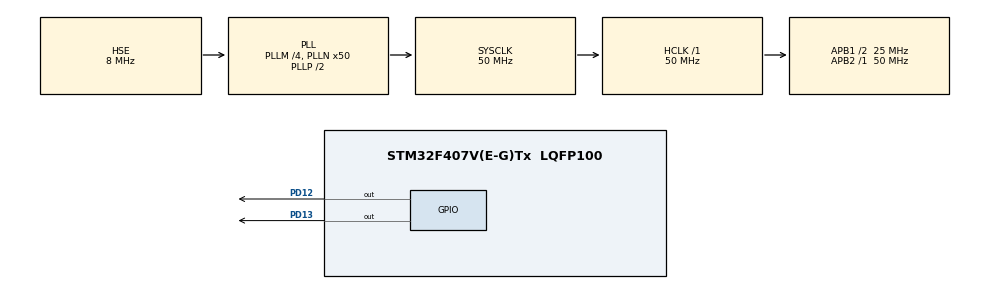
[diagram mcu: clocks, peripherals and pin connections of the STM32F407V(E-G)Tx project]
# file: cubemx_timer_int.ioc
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Mcu.Family=STM32F4
Mcu.Name=STM32F407V(E-G)Tx
Mcu.Package=LQFP100
NVIC.PriorityGroup=NVIC_PRIORITYGROUP_4
NVIC.TIM6_DAC_IRQn=true\:0\:0\:false\:true\:true\:2\:true\:true\:true
NVIC.TIM7_IRQn=true\:0\:0\:false\:true\:true\:1\:true\:true\:true
PD12.Signal=GPIO_Output
PD13.Signal=GPIO_Output
PH0-OSC_IN.Mode=HSE-External-Oscillator
PH0-OSC_IN.Signal=RCC_OSC_IN
PH1-OSC_OUT.Mode=HSE-External-Oscillator
PH1-OSC_OUT.Signal=RCC_OSC_OUT
ProjectManager.HeapSize=0x200
ProjectManager.StackSize=0x400
ProjectManager.TargetToolchain=STM32CubeIDE
RCC.48MHZClocksFreq_Value=25000000
RCC.AHBFreq_Value=50000000
RCC.APB1CLKDivider=RCC_HCLK_DIV2
RCC.APB1Freq_Value=25000000
RCC.APB1TimFreq_Value=50000000
RCC.APB2Freq_Value=50000000
RCC.APB2TimFreq_Value=50000000
RCC.CortexFreq_Value=50000000
RCC.HCLKFreq_Value=50000000
RCC.HSE_VALUE=8000000
RCC.HSI_VALUE=16000000
RCC.LSE_VALUE=32768
RCC.PLLM=4
RCC.PLLN=50
RCC.PLLSourceVirtual=RCC_PLLSOURCE_HSE
RCC.SYSCLKFreq_VALUE=50000000
RCC.SYSCLKSource=RCC_SYSCLKSOURCE_PLLCLK
RCC.VCOOutputFreq_Value=100000000
TIM6.AutoReloadPreload=TIM_AUTORELOAD_PRELOAD_ENABLE
TIM6.Period=500
TIM6.Prescaler=50000
TIM7.AutoReloadPreload=TIM_AUTORELOAD_PRELOAD_ENABLE
TIM7.Period=8399
TIM7.Prescaler=9999
TIM7.TIM_MasterOutputTrigger=TIM_TRGO_UPDATE
VP_TIM6_VS_ClockSourceINT.Mode=Enable_Timer
VP_TIM7_VS_ClockSourceINT.Mode=Enable_Timer
board=custom

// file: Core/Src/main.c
/* USER CODE BEGIN Header */
/**
  ******************************************************************************
  * @file           : main.c
  * @brief          : Main program body
  ******************************************************************************
  * @attention
  *
  * Copyright (c) 2024 STMicroelectronics.
  * All rights reserved.
  *
  * This software is licensed under terms that can be found in the LICENSE file
  * in the root directory of this software component.
  * If no LICENSE file comes with this software, it is provided AS-IS.
  *
  ******************************************************************************
  */
/* USER CODE END Header */
#include "main.h"

TIM_HandleTypeDef htim6;
TIM_HandleTypeDef htim7;

/* USER CODE BEGIN PV */
uint8_t f_led_12 = 0;
uint8_t f_led_13 = 0;
/* USER CODE END PV */

void SystemClock_Config(void);
static void MX_GPIO_Init(void);
static void MX_TIM7_Init(void);
static void MX_TIM6_Init(void);
static void MX_NVIC_Init(void);

int main(void)
{

  /* MCU Configuration--------------------------------------------------------*/

  /* Reset of all peripherals, Initializes the Flash interface and the Systick. */
  HAL_Init();

  /* Configure the system clock */
  SystemClock_Config();

  /* Initialize all configured peripherals */
  MX_GPIO_Init();
  MX_TIM7_Init();
  MX_TIM6_Init();

  /* Initialize interrupts */
  MX_NVIC_Init();
  /* USER CODE BEGIN 2 */
  HAL_TIM_Base_Start_IT(&htim7);
  HAL_TIM_Base_Start_IT(&htim6);
  /* USER CODE END 2 */

  /* Infinite loop */
  /* USER CODE BEGIN WHILE */
  while (1)
  {if(f_led_13 == 1){
		HAL_GPIO_TogglePin(GPIOD, GPIO_PIN_13);
		f_led_13 = 0;
	}else if (f_led_12 == 1){
		HAL_GPIO_TogglePin(GPIOD, GPIO_PIN_12);
		f_led_12 = 0;
	}
    /* USER CODE END WHILE */

  }
}

void SystemClock_Config(void)
{
  RCC_OscInitTypeDef RCC_OscInitStruct = {0};
  RCC_ClkInitTypeDef RCC_ClkInitStruct = {0};

  /** Configure the main internal regulator output voltage
  */
  __HAL_RCC_PWR_CLK_ENABLE();
  __HAL_PWR_VOLTAGESCALING_CONFIG(PWR_REGULATOR_VOLTAGE_SCALE1);

  /** Initializes the RCC Oscillators according to the specified parameters
  * in the RCC_OscInitTypeDef structure.
  */
  RCC_OscInitStruct.OscillatorType = RCC_OSCILLATORTYPE_HSE;
  RCC_OscInitStruct.HSEState = RCC_HSE_ON;
  RCC_OscInitStruct.PLL.PLLState = RCC_PLL_ON;
  RCC_OscInitStruct.PLL.PLLSource = RCC_PLLSOURCE_HSE;
  RCC_OscInitStruct.PLL.PLLM = 4;
  RCC_OscInitStruct.PLL.PLLN = 50;
  RCC_OscInitStruct.PLL.PLLP = RCC_PLLP_DIV2;
  RCC_OscInitStruct.PLL.PLLQ = 4;
  if (HAL_RCC_OscConfig(&RCC_OscInitStruct) != HAL_OK)
  {
    Error_Handler();
  }

  /** Initializes the CPU, AHB and APB buses clocks
  */
  RCC_ClkInitStruct.ClockType = RCC_CLOCKTYPE_HCLK|RCC_CLOCKTYPE_SYSCLK
                              |RCC_CLOCKTYPE_PCLK1|RCC_CLOCKTYPE_PCLK2;
  RCC_ClkInitStruct.SYSCLKSource = RCC_SYSCLKSOURCE_PLLCLK;
  RCC_ClkInitStruct.AHBCLKDivider = RCC_SYSCLK_DIV1;
  RCC_ClkInitStruct.APB1CLKDivider = RCC_HCLK_DIV2;
  RCC_ClkInitStruct.APB2CLKDivider = RCC_HCLK_DIV1;

  if (HAL_RCC_ClockConfig(&RCC_ClkInitStruct, FLASH_LATENCY_1) != HAL_OK)
  {
    Error_Handler();
  }
}

/**
  * @brief NVIC Configuration.
  * @retval None
  */
static void MX_NVIC_Init(void)
{
  /* TIM7_IRQn interrupt configuration */
  HAL_NVIC_SetPriority(TIM7_IRQn, 0, 0);
  HAL_NVIC_EnableIRQ(TIM7_IRQn);
  /* TIM6_DAC_IRQn interrupt configuration */
  HAL_NVIC_SetPriority(TIM6_DAC_IRQn, 0, 0);
  HAL_NVIC_EnableIRQ(TIM6_DAC_IRQn);
}

static void MX_TIM6_Init(void)
{

  TIM_MasterConfigTypeDef sMasterConfig = {0};

  htim6.Instance = TIM6;
  htim6.Init.Prescaler = 50000;
  htim6.Init.CounterMode = TIM_COUNTERMODE_UP;
  htim6.Init.Period = 500;
  htim6.Init.AutoReloadPreload = TIM_AUTORELOAD_PRELOAD_ENABLE;
  if (HAL_TIM_Base_Init(&htim6) != HAL_OK)
  {
    Error_Handler();
  }
  sMasterConfig.MasterOutputTrigger = TIM_TRGO_RESET;
  sMasterConfig.MasterSlaveMode = TIM_MASTERSLAVEMODE_DISABLE;
  if (HAL_TIMEx_MasterConfigSynchronization(&htim6, &sMasterConfig) != HAL_OK)
  {
    Error_Handler();
  }

}

static void MX_TIM7_Init(void)
{

  TIM_MasterConfigTypeDef sMasterConfig = {0};

  htim7.Instance = TIM7;
  htim7.Init.Prescaler = 9999;
  htim7.Init.CounterMode = TIM_COUNTERMODE_UP;
  htim7.Init.Period = 8399;
  htim7.Init.AutoReloadPreload = TIM_AUTORELOAD_PRELOAD_ENABLE;
  if (HAL_TIM_Base_Init(&htim7) != HAL_OK)
  {
    Error_Handler();
  }
  sMasterConfig.MasterOutputTrigger = TIM_TRGO_UPDATE;
  sMasterConfig.MasterSlaveMode = TIM_MASTERSLAVEMODE_DISABLE;
  if (HAL_TIMEx_MasterConfigSynchronization(&htim7, &sMasterConfig) != HAL_OK)
  {
    Error_Handler();
  }

}

static void MX_GPIO_Init(void)
{
  GPIO_InitTypeDef GPIO_InitStruct = {0};

  /* GPIO Ports Clock Enable */
  __HAL_RCC_GPIOH_CLK_ENABLE();
  __HAL_RCC_GPIOD_CLK_ENABLE();

  /*Configure GPIO pin Output Level */
  HAL_GPIO_WritePin(GPIOD, GPIO_PIN_12|GPIO_PIN_13, GPIO_PIN_RESET);

  /*Configure GPIO pins : PD12 PD13 */
  GPIO_InitStruct.Pin = GPIO_PIN_12|GPIO_PIN_13;
  GPIO_InitStruct.Mode = GPIO_MODE_OUTPUT_PP;
  GPIO_InitStruct.Pull = GPIO_NOPULL;
  GPIO_InitStruct.Speed = GPIO_SPEED_FREQ_LOW;
  HAL_GPIO_Init(GPIOD, &GPIO_InitStruct);

}

/* USER CODE BEGIN 4 */
void HAL_TIM_PeriodElapsedCallback(TIM_HandleTypeDef *htim)
{
  //if (htim == &htim7) {
    //HAL_GPIO_TogglePin(GPIOD, GPIO_PIN_13);
	//  f_led_13 = 1;
  //}
  if (htim == &htim6) {
      HAL_GPIO_TogglePin(GPIOD, GPIO_PIN_12);
//	  f_led_12 = 1;
  }
}

/* USER CODE END 4 */

void Error_Handler(void)
{
  __disable_irq();
  while (1)
  {
  }
}
